VERSION ""

NS_ :

BS_:

BU_: QP_AccelGyro

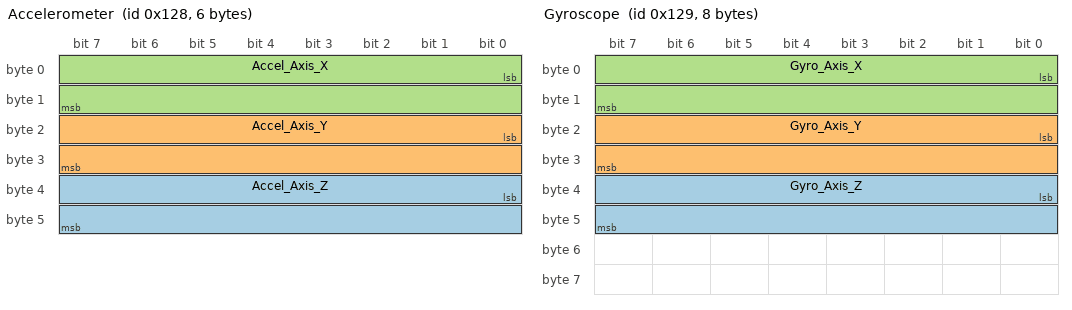
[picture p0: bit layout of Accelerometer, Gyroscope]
BO_ 296 Accelerometer: 6 QP_AccelGyro
 SG_ Accel_Axis_Z : 32|16@1- (0.001,0) [-16|16] "G" Vector__XXX
 SG_ Accel_Axis_Y : 16|16@1- (0.001,0) [-16|16] "G" Vector__XXX
 SG_ Accel_Axis_X : 0|16@1- (0.001,0) [-16|16] "G" Vector__XXX

BO_ 297 Gyroscope: 8 QP_AccelGyro
 SG_ Gyro_Axis_Z : 32|16@1- (0.001,0) [-500|500] "dps" Vector__XXX
 SG_ Gyro_Axis_Y : 16|16@1- (0.001,0) [-500|500] "dps" Vector__XXX
 SG_ Gyro_Axis_X : 0|16@1- (0.001,0) [-500|500] "dps" Vector__XXX
